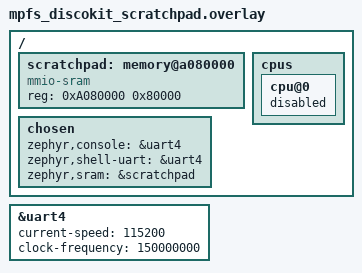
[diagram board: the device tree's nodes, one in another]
/ {
	scratchpad: memory@a080000 {
		compatible = "mmio-sram";
		reg = <0xA080000 0x80000>;
	};

	cpus {
		cpu@0 {
			status = "disabled";
		};
	};

	chosen {
		zephyr,console = &uart4;
		zephyr,shell-uart = &uart4;
		zephyr,sram = &scratchpad;
	};
};

&uart4 {
	status = "okay";
	current-speed = <115200>;
	clock-frequency = <150000000>;
};
